AUTOSAR XML (schema 314)
package /ComponentType
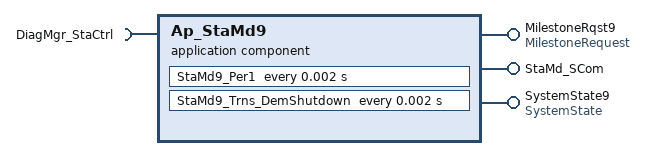
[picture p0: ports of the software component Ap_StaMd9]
  application software component type Ap_StaMd9
    provide port MilestoneRqst9: provided-interface=MilestoneRequest
      provided-com-specs:
        operation=WarmInitMilestoneComplete, queue-length=1
        operation=WarmInitMilestoneNotComplete, queue-length=1
    provide port StaMd_SCom: provided-com-specs=[{operation=EcuReset, queue-length=1}, {operation=FBLTransitionReq, queue-length=1}], provided-interface=StaMd_SCom
    provide port SystemState9: mode-switch-com-spec{mode-group=Mode, queue-length=1}, provided-interface=SystemState
    require port DiagMgr_StaCtrl: client-com-spec=Shutdown, required-interface=DiagMgr_StaCtrl
  internal behavior Ap_StaMd9_InternalBehavior: component=Ap_StaMd9
    4 x operation invoked event:
      OIT_MilestoneRqst9_WarmInitMilestoneComplete_MilestoneRqst9_WarmInitMilestoneComplete: start-on-event=MilestoneRqst9_WarmInitMilestoneComplete, operation=MilestoneRqst9.WarmInitMilestoneComplete
      OIT_MilestoneRqst9_WarmInitMilestoneNotComplete_MilestoneRqst9_WarmInitMilestoneNotComplete: start-on-event=MilestoneRqst9_WarmInitMilestoneNotComplete, operation=MilestoneRqst9.WarmInitMilestoneNotComplete
      OIT_StaMd_SCom_EcuReset_StaMd_SCom_EcuReset: start-on-event=StaMd_SCom_EcuReset, operation=StaMd_SCom.EcuReset
      OIT_StaMd_SCom_FBLTransitionReq_StaMd_SCom_FBLTransitionReq: start-on-event=StaMd_SCom_FBLTransitionReq, operation=StaMd_SCom.FBLTransitionReq
    timing event TMT_StaMd9_Per1: start-on-event=StaMd9_Per1, period=0.002
    timing event TMT_StaMd9_Trns_DemShutdown: start-on-event=StaMd9_Trns_DemShutdown, period=0.002
    exclusive area StaMds9_MilestoneRqst_WARMINIT_ExclArea
    port-api-options:
      enable-take-address=false, indirect-api=false, port=DiagMgr_StaCtrl
      enable-take-address=false, indirect-api=false, port=MilestoneRqst9
      enable-take-address=false, indirect-api=false, port=StaMd_SCom
      enable-take-address=false, indirect-api=false, port=SystemState9
    6 x runnable:
      MilestoneRqst9_WarmInitMilestoneComplete: can-be-invoked-concurrently=true, can-enter-exclusive-area=StaMds9_MilestoneRqst_WARMINIT_ExclArea
      MilestoneRqst9_WarmInitMilestoneNotComplete: can-be-invoked-concurrently=true, can-enter-exclusive-area=StaMds9_MilestoneRqst_WARMINIT_ExclArea
      StaMd_SCom_EcuReset
      StaMd_SCom_FBLTransitionReq
      StaMd9_Per1
        mode switch point SWITCH_SystemState9_Mode: mode-group=SystemState9.Mode
      StaMd9_Trns_DemShutdown
        sync call SC_DiagMgr_StaCtrl_Shutdown: operation=DiagMgr_StaCtrl.Shutdown, timeout=0
  swc implementation Ap_StaMd9_Implementation: behavior=Ap_StaMd9_InternalBehavior
    code-descriptors:
      code Code: type=SRC
